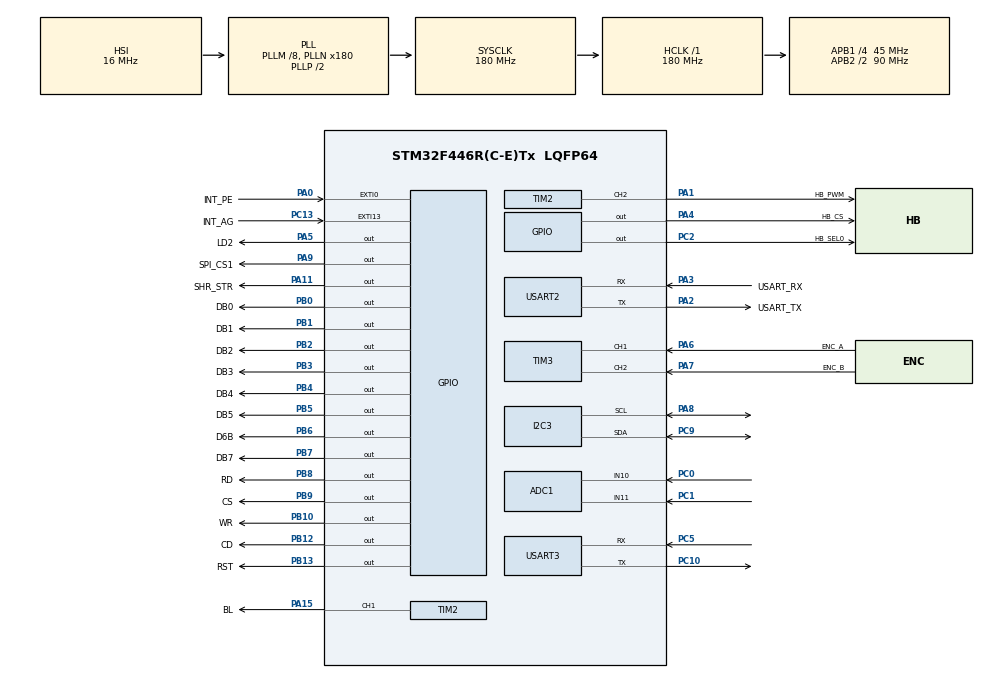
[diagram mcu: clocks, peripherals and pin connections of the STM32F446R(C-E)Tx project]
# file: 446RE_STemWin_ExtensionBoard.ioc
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ADC1.Channel-0\#ChannelRegularConversion=ADC_CHANNEL_10
ADC1.NbrOfConversionFlag=1
ADC1.Rank-0\#ChannelRegularConversion=1
ADC1.SamplingTime-0\#ChannelRegularConversion=ADC_SAMPLETIME_3CYCLES
ADC1.master=1
FREERTOS.Tasks01=InitTask,0,128,InitTask_Func,Default,NULL,Dynamic,NULL,NULL;MainTask,0,512,MainTask_Func,Default,NULL,Dynamic,NULL,NULL;GUI_Task,-3,2048,GUI_Task_Function,Default,NULL,Dynamic,NULL,NULL;InterruptTask,-3,256,InterruptTask_Func,Default,NULL,Dynamic,NULL,NULL
FREERTOS.configENABLE_FPU=1
FREERTOS.configUSE_NEWLIB_REENTRANT=1
FREERTOS.configUSE_TIMERS=1
Mcu.Family=STM32F4
Mcu.Name=STM32F446R(C-E)Tx
Mcu.Package=LQFP64
NVIC.EXTI0_IRQn=true\:5\:0\:false\:false\:true\:true\:true\:true\:true
NVIC.EXTI15_10_IRQn=true\:5\:0\:false\:false\:true\:true\:true\:true\:true
NVIC.PriorityGroup=NVIC_PRIORITYGROUP_4
NVIC.TIM7_IRQn=true\:15\:0\:false\:false\:true\:false\:false\:true\:true
NVIC.TimeBase=TIM7_IRQn
NVIC.TimeBaseIP=TIM7
PA0-WKUP.GPIO_Label=INT_PE
PA0-WKUP.Signal=GPXTI0
PA1.GPIO_Label=HB_PWM
PA1.Signal=S_TIM2_CH2
PA11.GPIO_Label=SHR_STR
PA11.Signal=GPIO_Output
PA13.GPIO_Label=SWDIO
PA13.Mode=Serial_Wire
PA13.Signal=SYS_JTMS-SWDIO
PA14.GPIO_Label=SWDCLK
PA14.Mode=Serial_Wire
PA14.Signal=SYS_JTCK-SWCLK
PA15.GPIO_Label=BL
PA15.Signal=S_TIM2_CH1_ETR
PA2.GPIO_Label=USART_TX
PA2.Mode=Asynchronous
PA2.Signal=USART2_TX
PA3.GPIO_Label=USART_RX
PA3.Mode=Asynchronous
PA3.Signal=USART2_RX
PA4.GPIO_Label=HB_CS
PA4.Signal=GPIO_Output
PA5.GPIO_Label=LD2
PA5.Signal=GPIO_Output
PA6.GPIO_Label=ENC_A
PA6.Signal=S_TIM3_CH1
PA7.GPIO_Label=ENC_B
PA7.Signal=S_TIM3_CH2
PA8.Mode=I2C
PA8.Signal=I2C3_SCL
PA9.GPIO_Label=SPI_CS1
PA9.Signal=GPIO_Output
PB0.GPIO_Label=DB0
PB0.Signal=GPIO_Output
PB1.GPIO_Label=DB1
PB1.Signal=GPIO_Output
PB10.GPIO_Label=WR
PB10.Signal=GPIO_Output
PB12.GPIO_Label=CD
PB12.Signal=GPIO_Output
PB13.GPIO_Label=RST
PB13.Signal=GPIO_Output
PB2.GPIO_Label=DB2
PB2.Signal=GPIO_Output
PB3.GPIO_Label=DB3
PB3.Signal=GPIO_Output
PB4.GPIO_Label=DB4
PB4.Signal=GPIO_Output
PB5.GPIO_Label=DB5
PB5.Signal=GPIO_Output
PB6.GPIO_Label=D6B
PB6.Signal=GPIO_Output
PB7.GPIO_Label=DB7
PB7.Signal=GPIO_Output
PB8.GPIO_Label=RD
PB8.Signal=GPIO_Output
PB9.GPIO_Label=CS
PB9.Signal=GPIO_Output
PC0.Signal=ADCx_IN10
PC1.Signal=ADCx_IN11
PC10.Mode=Asynchronous
PC10.Signal=USART3_TX
PC13.GPIO_Label=INT_AG
PC13.Signal=GPXTI13
PC2.GPIO_Label=HB_SEL0
PC2.Signal=GPIO_Output
PC5.Mode=Asynchronous
PC5.Signal=USART3_RX
PC9.Mode=I2C
PC9.Signal=I2C3_SDA
ProjectManager.HeapSize=0x200
ProjectManager.StackSize=0x400
ProjectManager.TargetToolchain=STM32CubeIDE
RCC.AHBFreq_Value=180000000
RCC.APB1CLKDivider=RCC_HCLK_DIV4
RCC.APB1Freq_Value=45000000
RCC.APB1TimFreq_Value=90000000
RCC.APB2CLKDivider=RCC_HCLK_DIV2
RCC.APB2Freq_Value=90000000
RCC.APB2TimFreq_Value=180000000
RCC.CortexFreq_Value=180000000
RCC.HCLKFreq_Value=180000000
RCC.PLLM=8
RCC.PLLN=180
RCC.SYSCLKFreq_VALUE=180000000
RCC.SYSCLKSource=RCC_SYSCLKSOURCE_PLLCLK
RCC.USBFreq_Value=180000000
RCC.VCOOutputFreq_Value=360000000
SH.ADCx_IN10.0=ADC1_IN10,IN10
SH.ADCx_IN11.0=ADC1_IN11,IN11
SH.S_TIM2_CH1_ETR.0=TIM2_CH1,PWM Generation1 CH1
SH.S_TIM2_CH2.0=TIM2_CH2,PWM Generation2 CH2
SH.S_TIM3_CH1.0=TIM3_CH1,Encoder_Interface
SH.S_TIM3_CH2.0=TIM3_CH2,Encoder_Interface
TIM2.AutoReloadPreload=TIM_AUTORELOAD_PRELOAD_ENABLE
TIM2.Channel-PWM\ Generation1\ CH1=TIM_CHANNEL_1
TIM2.Channel-PWM\ Generation2\ CH2=TIM_CHANNEL_2
TIM2.Period=100
TIM2.Prescaler=840
TIM3.AutoReloadPreload=TIM_AUTORELOAD_PRELOAD_ENABLE
USART2.VirtualMode=VM_ASYNC
USART3.VirtualMode=VM_ASYNC
VP_CRC_VS_CRC.Mode=CRC_Activate
VP_FREERTOS_VS_CMSIS_V1.Mode=CMSIS_V1
VP_SYS_VS_tim7.Mode=TIM7
VP_TIM2_VS_ClockSourceINT.Mode=Internal
board=custom

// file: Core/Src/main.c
/* USER CODE BEGIN Header */
/**
  ******************************************************************************
  * @file           : main.c
  * @brief          : Main program body
  ******************************************************************************
  * @attention
  *
  * Copyright (c) 2023 STMicroelectronics.
  * All rights reserved.
  *
  * This software is licensed under terms that can be found in the LICENSE file
  * in the root directory of this software component.
  * If no LICENSE file comes with this software, it is provided AS-IS.
  *
  ******************************************************************************
  */
/* USER CODE END Header */
#include "main.h"
#include "cmsis_os.h"
#include "adc.h"
#include "crc.h"
#include "i2c.h"
#include "tim.h"
#include "usart.h"
#include "gpio.h"

void SystemClock_Config(void);
void MX_FREERTOS_Init(void);

int main(void)
{

  /* MCU Configuration--------------------------------------------------------*/

  /* Reset of all peripherals, Initializes the Flash interface and the Systick. */
  HAL_Init();

  /* Configure the system clock */
  SystemClock_Config();

  /* Initialize all configured peripherals */
  MX_GPIO_Init();
  MX_CRC_Init();
  MX_TIM2_Init();
  MX_TIM3_Init();
  MX_USART2_UART_Init();
  MX_ADC1_Init();
  MX_I2C3_Init();
  MX_USART3_UART_Init();

  /* Call init function for freertos objects (in freertos.c) */
  MX_FREERTOS_Init();

  /* Start scheduler */
  osKernelStart();
  /* We should never get here as control is now taken by the scheduler */
  /* Infinite loop */
  while (1)
  {

  }
}

void SystemClock_Config(void)
{
  RCC_OscInitTypeDef RCC_OscInitStruct = {0};
  RCC_ClkInitTypeDef RCC_ClkInitStruct = {0};

  /** Configure the main internal regulator output voltage
  */
  __HAL_RCC_PWR_CLK_ENABLE();
  __HAL_PWR_VOLTAGESCALING_CONFIG(PWR_REGULATOR_VOLTAGE_SCALE1);

  /** Initializes the RCC Oscillators according to the specified parameters
  * in the RCC_OscInitTypeDef structure.
  */
  RCC_OscInitStruct.OscillatorType = RCC_OSCILLATORTYPE_HSI;
  RCC_OscInitStruct.HSIState = RCC_HSI_ON;
  RCC_OscInitStruct.HSICalibrationValue = RCC_HSICALIBRATION_DEFAULT;
  RCC_OscInitStruct.PLL.PLLState = RCC_PLL_ON;
  RCC_OscInitStruct.PLL.PLLSource = RCC_PLLSOURCE_HSI;
  RCC_OscInitStruct.PLL.PLLM = 8;
  RCC_OscInitStruct.PLL.PLLN = 180;
  RCC_OscInitStruct.PLL.PLLP = RCC_PLLP_DIV2;
  RCC_OscInitStruct.PLL.PLLQ = 2;
  RCC_OscInitStruct.PLL.PLLR = 2;
  if (HAL_RCC_OscConfig(&RCC_OscInitStruct) != HAL_OK)
  {
    Error_Handler();
  }

  /** Activate the Over-Drive mode
  */
  if (HAL_PWREx_EnableOverDrive() != HAL_OK)
  {
    Error_Handler();
  }

  /** Initializes the CPU, AHB and APB buses clocks
  */
  RCC_ClkInitStruct.ClockType = RCC_CLOCKTYPE_HCLK|RCC_CLOCKTYPE_SYSCLK
                              |RCC_CLOCKTYPE_PCLK1|RCC_CLOCKTYPE_PCLK2;
  RCC_ClkInitStruct.SYSCLKSource = RCC_SYSCLKSOURCE_PLLCLK;
  RCC_ClkInitStruct.AHBCLKDivider = RCC_SYSCLK_DIV1;
  RCC_ClkInitStruct.APB1CLKDivider = RCC_HCLK_DIV4;
  RCC_ClkInitStruct.APB2CLKDivider = RCC_HCLK_DIV2;

  if (HAL_RCC_ClockConfig(&RCC_ClkInitStruct, FLASH_LATENCY_5) != HAL_OK)
  {
    Error_Handler();
  }
}

void HAL_TIM_PeriodElapsedCallback(TIM_HandleTypeDef *htim)
{
  if (htim->Instance == TIM7) {
    HAL_IncTick();
  }
}

void Error_Handler(void)
{
  __disable_irq();
  while (1)
  {
  }
}

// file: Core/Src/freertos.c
/* USER CODE BEGIN Header */
/**
  ******************************************************************************
  * File Name          : freertos.c
  * Description        : Code for freertos applications
  ******************************************************************************
  * @attention
  *
  * Copyright (c) 2023 STMicroelectronics.
  * All rights reserved.
  *
  * This software is licensed under terms that can be found in the LICENSE file
  * in the root directory of this software component.
  * If no LICENSE file comes with this software, it is provided AS-IS.
  *
  ******************************************************************************
  */
/* USER CODE END Header */

#include "FreeRTOS.h"
#include "task.h"
#include "main.h"
#include "cmsis_os.h"

/* USER CODE BEGIN Includes */
#include "ExtensionBoard.h"
/* USER CODE END Includes */

osThreadId InitTaskHandle;
osThreadId MainTaskHandle;
osThreadId GUI_TaskHandle;
osThreadId InterruptTaskHandle;

void InitTask_Func(void const * argument);
void MainTask_Func(void const * argument);
void GUI_Task_Function(void const * argument);
void InterruptTask_Func(void const * argument);

void MX_FREERTOS_Init(void); /* (MISRA C 2004 rule 8.1) */

/* GetIdleTaskMemory prototype (linked to static allocation support) */
void vApplicationGetIdleTaskMemory( StaticTask_t **ppxIdleTaskTCBBuffer, StackType_t **ppxIdleTaskStackBuffer, uint32_t *pulIdleTaskStackSize );

/* GetTimerTaskMemory prototype (linked to static allocation support) */
void vApplicationGetTimerTaskMemory( StaticTask_t **ppxTimerTaskTCBBuffer, StackType_t **ppxTimerTaskStackBuffer, uint32_t *pulTimerTaskStackSize );

/* USER CODE BEGIN GET_IDLE_TASK_MEMORY */
static StaticTask_t xIdleTaskTCBBuffer;
static StackType_t xIdleStack[configMINIMAL_STACK_SIZE];

void vApplicationGetIdleTaskMemory( StaticTask_t **ppxIdleTaskTCBBuffer, StackType_t **ppxIdleTaskStackBuffer, uint32_t *pulIdleTaskStackSize )
{
  *ppxIdleTaskTCBBuffer = &xIdleTaskTCBBuffer;
  *ppxIdleTaskStackBuffer = &xIdleStack[0];
  *pulIdleTaskStackSize = configMINIMAL_STACK_SIZE;
  /* place for user code */
}
/* USER CODE END GET_IDLE_TASK_MEMORY */

/* USER CODE BEGIN GET_TIMER_TASK_MEMORY */
static StaticTask_t xTimerTaskTCBBuffer;
static StackType_t xTimerStack[configTIMER_TASK_STACK_DEPTH];

void vApplicationGetTimerTaskMemory( StaticTask_t **ppxTimerTaskTCBBuffer, StackType_t **ppxTimerTaskStackBuffer, uint32_t *pulTimerTaskStackSize )
{
  *ppxTimerTaskTCBBuffer = &xTimerTaskTCBBuffer;
  *ppxTimerTaskStackBuffer = &xTimerStack[0];
  *pulTimerTaskStackSize = configTIMER_TASK_STACK_DEPTH;
  /* place for user code */
}
/* USER CODE END GET_TIMER_TASK_MEMORY */

void MX_FREERTOS_Init(void) {

  /* Create the thread(s) */
  /* definition and creation of InitTask */
  osThreadDef(InitTask, InitTask_Func, osPriorityNormal, 0, 128);
  InitTaskHandle = osThreadCreate(osThread(InitTask), NULL);

  /* definition and creation of MainTask */
  osThreadDef(MainTask, MainTask_Func, osPriorityNormal, 0, 512);
  MainTaskHandle = osThreadCreate(osThread(MainTask), NULL);

  /* definition and creation of GUI_Task */
  osThreadDef(GUI_Task, GUI_Task_Function, osPriorityIdle, 0, 2048);
  GUI_TaskHandle = osThreadCreate(osThread(GUI_Task), NULL);

  /* definition and creation of InterruptTask */
  osThreadDef(InterruptTask, InterruptTask_Func, osPriorityIdle, 0, 256);
  InterruptTaskHandle = osThreadCreate(osThread(InterruptTask), NULL);

}

void InitTask_Func(void const * argument)
{
  for(;;)
  {
    osDelay(1);
  }
}

void MainTask_Func(void const * argument)
{
  for(;;)
  {
    osDelay(1);
  }
}

void GUI_Task_Function(void const * argument)
{
  /* USER CODE BEGIN GUI_Task_Function */
	BoardInit();
  /* Infinite loop */
  for(;;)
  {
	  MainTask();
    osDelay(80);
  }
  /* USER CODE END GUI_Task_Function */
}

void InterruptTask_Func(void const * argument)
{
  for(;;)
  {
    osDelay(1);
  }
}
